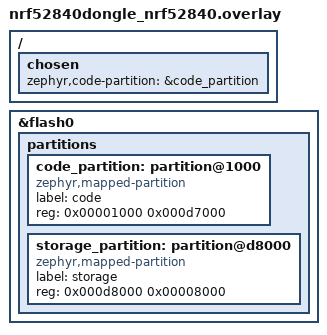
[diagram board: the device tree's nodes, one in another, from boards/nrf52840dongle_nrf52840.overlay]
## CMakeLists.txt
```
# Cremind Tag gateway firmware (docs/gateway-firmware.md). Built by
# tools/build.py with -DZEPHYR_EXTRA_MODULES=<repository>, which provides lib/.
cmake_minimum_required(VERSION 3.20.0)
find_package(Zephyr REQUIRED HINTS $ENV{ZEPHYR_BASE})
project(cremind_gateway)

target_sources(app PRIVATE
  src/main.c
  src/mesh.c
  src/store.c
  src/gw_thread.c
  src/uart_io.c
  src/core/gw_core.c
  src/core/gw_serial.c
  src/core/gw_lane.c
  src/core/gw_delivery.c
  src/core/gw_nodes.c
  src/core/gw_ring.c)
# Protocol v2 (docs/connect-setup.md): secure sessions, ownership, tunnels,
# and the physical factory reset.
target_sources_ifdef(CONFIG_CTAG_GW_SECURE app PRIVATE
  src/reset.c
  src/core/gw_secure.c
  src/core/gw_tunnel.c)
# Tags on the gateway's own radio (docs/protocol.md 11): the relay core and
# its Bluetooth side (lib/sched and lib/frag come with CONFIG_CTAG_GW_RADIO).
target_sources_ifdef(CONFIG_CTAG_GW_RADIO app PRIVATE
  src/central.c
  src/core/gw_radio.c)
target_include_directories(app PRIVATE src src/core)
```

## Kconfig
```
# Cremind Tag gateway application options (docs/gateway-firmware.md).

rsource "Kconfig.gateway"

source "Kconfig.zephyr"
```

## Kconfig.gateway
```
# Gateway options shared by the application (Kconfig) and its native_sim
# builds (tests/*/Kconfig). docs/gateway-firmware.md explains each.

menu "Cremind Tag gateway"

config CTAG_GW_BOARD_ID
	int "Protocol board id reported in caps.board"
	default 1
	help
	  protocol/spec.yaml boards: 1 = NRF52840DK_GATEWAY, 2 =
	  NRF52832_GATEWAY. Set per SoC in socs/<soc>.conf.

config CTAG_GW_SERIAL_CREDITS
	int "Serial: requests the host may have outstanding (caps.credits)"
	default 4
	range 1 32
	help
	  Every request is processed as soon as its frame completes; its
	  response waits in one of these slots until the host grants a credit.
	  The credit of a request is returned with its response.

config CTAG_GW_TX_FRAME
	int "Serial: largest decoded frame the gateway sends (bytes)"
	default 2048
	range 512 4096
	help
	  Bounds INFO, LIST_NODES and GET_INVENTORY answers and EVT_BRIDGE_INFO.
	  A full inventory (MAX_BRIDGES bridges, MAX_TAGS assignments, health
	  counters) needs about 1.9 KiB.

config CTAG_GW_EVENT_MAX
	int "Serial: largest retained event payload (bytes)"
	default 104
	range 100 255
	help
	  One slot of the SERIAL_EVENT_RETAIN ring. EVT_RESULT, the largest
	  retained event, encodes to at most 100 bytes (every field at its
	  largest value, flags and stored_epoch included).

config CTAG_GW_EVQ_BYTES
	int "Serial: best-effort event FIFO (bytes)"
	default 1024
	range 256 8192
	help
	  EVT_STAGE, EVT_UNPROV_BEACON, EVT_TAG_SEEN, EVT_BRIDGE_INFO and EVT_LOG
	  waiting for a host credit; a full FIFO drops the new event
	  (events_discarded).

config CTAG_GW_DELIVERY_QUEUE
	int "Delivery queue: layouts waiting behind the active transfer"
	default 4
	range 1 16
	help
	  DELIVER_LAYOUT answers BUSY when this many layouts are queued, or when
	  the layout arena has no room for the new one.

config CTAG_GW_LAYOUT_ARENA
	int "Delivery queue: bytes for the queued and active layouts"
	default 20480
	range 4096 65536
	help
	  Layouts are stored back to back (4-byte header, 4-byte aligned) and
	  released in order. At least CTAG_GW_LAYOUT_MAX + 4 so that the largest
	  layout always fits an empty queue; typical layouts are about 1 KiB.

config CTAG_GW_LAYOUT_MAX
	int "Delivery queue: largest layout accepted (bytes)"
	default 4000
	range 150 4096
	help
	  LAYOUT_SERIAL_MAX (4000) is the largest layout the companion sends;
	  anything larger answers TOO_LARGE.

config CTAG_GW_AT_BRIDGE
	int "Deliveries remembered while their bridge works on them"
	default 16
	range 1 64
	help
	  Validated layouts waiting for their DELIVERY_RESULT (for CANCEL_DELIVERY
	  and timing.mesh_ms). The oldest entry is forgotten when full.

config CTAG_GW_MESH_OPS
	int "ASSIGN_TAG / UNASSIGN_TAG / TAG_COMMAND operations in flight"
	default 8
	range 1 32

config CTAG_GW_RESULT_DEDUP
	int "(bridge, result_seq) pairs remembered for de-duplication"
	default 64
	range 8 512

config CTAG_GW_REPORTED
	int "update_ids remembered as reported (one EVT_RESULT each)"
	default 64
	range 8 512
	help
	  docs/protocol.md 10: exactly one EVT_RESULT per update_id. A later
	  result for a remembered update_id is acknowledged to the bridge and
	  dropped.

config CTAG_GW_ASSIGN_MAX
	int "Assignments remembered for the inventory"
	default 32
	range 1 128

config CTAG_GW_NAME_MAX
	int "Longest bridge name kept (bytes)"
	default 32
	range 8 64

config CTAG_GW_UNSEG_QUEUE
	int "Unsegmented mesh messages waiting for an advertising buffer"
	default 16
	range 4 64

config CTAG_GW_TAG_SEEN_INTERVAL_MS
	int "EVT_TAG_SEEN: minimum interval per (bridge, tag) (ms)"
	default 10000
	range 0 600000

config CTAG_GW_STATUS_TIMEOUT_MS
	int "LAYOUT_STATUS wait after a commit (ms)"
	default 10000

config CTAG_GW_REPLY_TIMEOUT_MS
	int "ASSIGN_STATUS and configuration-client reply wait (ms)"
	default 5000

config CTAG_GW_PROVISION_TIMEOUT_MS
	int "Provisioning guard: EVT_PROVISIONED TIMEOUT after (ms)"
	default 90000

config CTAG_GW_UART_RX_RING
	int "Serial driver: receive ring (bytes)"
	default 1024

config CTAG_GW_UART_TX_RING
	int "Serial driver: transmit ring (bytes)"
	default 1024

config CTAG_GW_EVQ_DEPTH
	int "Mesh/provisioning events queued for the gateway loop"
	default 24

config CTAG_GW_SECURE
	bool "Protocol v2: identity, ownership and secure sessions"
	select CTAG_SECURE
	help
	  docs/connect-setup.md: IDENTIFY, SECURE_OPEN and SECURE_DATA in
	  plaintext, everything else only inside a Noise IK session and only
	  as the access table of 4.2 allows; CLAIM, RECOVER, RELEASE, STATUS;
	  PROVISION with static OOB; DISCOVER and mesh tunnels. Without it the
	  gateway speaks protocol v1 (docs/gateway-firmware.md says which
	  boards run which).

if CTAG_GW_SECURE

config CTAG_GW_TUNNELS
	int "Mesh tunnels open at once (one per bridge)"
	default 2
	range 1 5

config CTAG_GW_DISCOVERED_SLOTS
	int "EVT_DISCOVERED rate limiter entries ((bridge, tag) pairs)"
	default 16
	range 4 64

config CTAG_GW_RADIO
	bool "Tags on the gateway's own radio (docs/protocol.md 11)"
	select CTAG_SCHED
	select CTAG_FRAG
	help
	  The gateway also connects to tags itself, as a thin BLE relay:
	  TUNNEL_OPEN / DISCOVER with bridge GATEWAY_ADDR use its own radio,
	  the companion runs the tag session and renders, and the gateway
	  carries whole messages (fragmented per 5.3) between the serial
	  tunnel and the tag's characteristics. Connections follow the mesh
	  suspend window of 5.2 (lib/sched). Protocol v2 only (it depends on
	  CTAG_GW_SECURE: tunnels and DISCOVER are v2 messages). Needs
	  BT_CENTRAL and BT_GATT_CLIENT; HELLO caps report tag_links.

if CTAG_GW_RADIO

config CTAG_GW_TAG_LINKS
	int "Tag connections held at once (caps.tag_links)"
	default 2
	range 1 2
	help
	  One Bluetooth connection each (CONFIG_BT_MAX_CONN >= this) and, per
	  link, the transmit queue of its tunnel (two messages) and the
	  reassembly buffers of what the tag sends.

config CTAG_GW_RADIO_TUNNELS
	int "Own-radio tunnels open at once (waiting or connected)"
	default 8
	range 1 16
	help
	  TUNNEL_OPEN to GATEWAY_ADDR answers BUSY beyond this. A waiting
	  tunnel costs a few bytes; its buffers are the link's once it is
	  connected.

config CTAG_GW_LINK_INFLIGHT
	int "DATA fragments handed to the Bluetooth host at once, per link"
	default 4
	range 1 16
	help
	  Writes without response in flight on one link. Kept below
	  CONFIG_BT_ATT_TX_COUNT (times the links) so that a write never
	  waits for an ATT buffer on the gateway loop.

# The shared scheduler (lib/sched): one link per tag link (gw_radio.c asserts
# it) and a back-off entry per tag it may be trying (one per own-radio tunnel
# at the default).
config CTAG_SCHED_LINKS
	default CTAG_GW_TAG_LINKS

config CTAG_SCHED_TAGS
	default 8

endif # CTAG_GW_RADIO

endif

endmenu
```

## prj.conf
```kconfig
# Cremind Tag gateway: every target. Per-SoC fragments in socs/, per-board in
# boards/ (docs/building.md). Debug logging over RTT: debug/rtt.conf
# (docs/gateway-firmware.md "Debugging").

# ---- Libraries (docs/firmware-libs.md) ----
CONFIG_CTAG_FRAME=y
CONFIG_CTAG_CBOR=y

# ---- Bluetooth: the Zephyr controller (bt-ll-sw-split snippet); the mesh
# needs only an observer and a broadcaster, never a connection. The nRF52840's
# tag links on its own radio add a central with a GATT client
# (socs/nrf52840.conf) ----
CONFIG_BT=y
CONFIG_BT_OBSERVER=y
CONFIG_BT_BROADCASTER=y
CONFIG_BT_CENTRAL=n
CONFIG_BT_PERIPHERAL=n
CONFIG_BT_SMP=n
CONFIG_BT_SETTINGS=y
CONFIG_BT_DEVICE_NAME="Cremind Tag gateway"
# Keep controller crypto (firmware-notes correction 8).
CONFIG_BT_CTLR_CRYPTO=y
CONFIG_BT_CTLR_DUP_FILTER_LEN=0
CONFIG_BT_CTLR_PRIVACY=n

# ---- Bluetooth Mesh: provisioner, CDB, configuration client (protocol.md 2) ----
CONFIG_BT_MESH=y
CONFIG_BT_MESH_PROVISIONER=y
CONFIG_BT_MESH_PROVISIONEE=n
CONFIG_BT_MESH_PB_ADV=y
CONFIG_BT_MESH_PB_GATT=n
CONFIG_BT_MESH_GATT_PROXY=n
CONFIG_BT_MESH_FRIEND=n
CONFIG_BT_MESH_LOW_POWER=n
CONFIG_BT_MESH_RELAY=n
CONFIG_BT_MESH_CDB=y
# The gateway itself plus MAX_BRIDGES bridges.
CONFIG_BT_MESH_CDB_NODE_COUNT=6
CONFIG_BT_MESH_CDB_SUBNET_COUNT=1
CONFIG_BT_MESH_CDB_APP_KEY_COUNT=1
CONFIG_BT_MESH_SUBNET_COUNT=1
CONFIG_BT_MESH_APP_KEY_COUNT=1
CONFIG_BT_MESH_MODEL_KEY_COUNT=1
CONFIG_BT_MESH_MODEL_GROUP_COUNT=1
CONFIG_BT_MESH_LABEL_COUNT=0
CONFIG_BT_MESH_CFG_CLI=y
CONFIG_BT_MESH_HEALTH_CLI=y
# Never the legacy advertiser (firmware-notes correction 4).
CONFIG_BT_MESH_ADV_EXT=y
CONFIG_BT_MESH_DEFAULT_TTL=5
CONFIG_BT_MESH_NETWORK_TRANSMIT_COUNT=3
CONFIG_BT_MESH_NETWORK_TRANSMIT_INTERVAL=20
# 160-byte vendor parameters need >= MESH_MIN_SEG segments. The gateway sends
# one segmented message at a time (3.2 rule 1); the second slot only absorbs a
# configuration-client message whose status came before its segment ACK.
CONFIG_BT_MESH_TX_SEG_MAX=16
CONFIG_BT_MESH_RX_SEG_MAX=16
CONFIG_BT_MESH_TX_SEG_MSG_COUNT=2
# Results (DELIVERY_RESULT, 44 access bytes) from several bridges at once.
CONFIG_BT_MESH_RX_SEG_MSG_COUNT=4
CONFIG_BT_MESH_ADV_BUF_COUNT=16
CONFIG_BT_MESH_CRPL=16
# Replay list written every 10 minutes, not on every message (flash wear).
CONFIG_BT_MESH_RPL_STORE_TIMEOUT=600

# ---- Storage: mesh state and the gateway's records (settings on NVS) ----
# Link into the code partition so the image can never grow into the settings.
CONFIG_USE_DT_CODE_PARTITION=y
CONFIG_FLASH=y
CONFIG_FLASH_MAP=y
CONFIG_FLASH_PAGE_LAYOUT=y
CONFIG_NVS=y
CONFIG_SETTINGS=y

# ---- Crypto: PSA (the mesh requires it); SHA-256 for the layout digest ----
CONFIG_PSA_WANT_ALG_SHA_256=y
CONFIG_ENTROPY_GENERATOR=y
# With BT_SETTINGS every mesh key is a persistent PSA key (secure storage):
# the subnet's derived keys, the app key, the device key, and in the CDB the
# net key, the app key and one device key per node (MAX_BRIDGES + 1), plus the
# provisioning ECDH key (firmware-notes 3). NCS defaults to 16 slots.
CONFIG_MBEDTLS_PSA_KEY_SLOT_COUNT=24

# ---- Advertising: the provisioner's own messages only (no relay, proxy or
# friend sets; NCS sizes 5 for a relay node) ----
CONFIG_BT_EXT_ADV_MAX_ADV_SET=1
CONFIG_BT_CTLR_ADV_SET=1

# ---- Kernel and drivers ----
CONFIG_SERIAL=y
CONFIG_UART_INTERRUPT_DRIVEN=y
CONFIG_RING_BUFFER=y
CONFIG_HWINFO=y
CONFIG_REBOOT=y
# Bluetooth API from cooperative threads only (the mesh provisioner sample).
CONFIG_MAIN_THREAD_PRIORITY=-2

# ---- Release build: no console or logging (the serial link belongs to the
# companion); debug/rtt.conf routes logs to RTT. ----
CONFIG_LOG=n
CONFIG_CONSOLE=n
CONFIG_UART_CONSOLE=n
CONFIG_PRINTK=n
CONFIG_ASSERT=n
CONFIG_BOOT_BANNER=n
CONFIG_NCS_BOOT_BANNER=n
```

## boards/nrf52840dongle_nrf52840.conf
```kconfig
# nRF52840 Dongle gateway (boards/nrf52840dongle_nrf52840.overlay). The board
# makes its USB port a CDC ACM console by default; here the port belongs to
# the companion's link alone (socs/nrf52840.conf), as on the DK.
CONFIG_BOARD_SERIAL_BACKEND_CDC_ACM=n
```

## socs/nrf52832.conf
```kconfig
# nRF52832 gateway (board id NRF52832_GATEWAY): UART (CH340 on the board, the
# interface MCU's virtual COM port on the nRF52 DK), 64 KiB RAM. Subject to
# resource qualification (docs/qualification/nrf52832_gateway.md).
CONFIG_CTAG_GW_BOARD_ID=2

# Stacks trimmed from the provisioner sample's figures; must be re-measured
# with debug/rtt.conf (CONFIG_THREAD_ANALYZER) during qualification. main runs
# the start-up and then the gateway loop.
CONFIG_MAIN_STACK_SIZE=3072
CONFIG_SYSTEM_WORKQUEUE_STACK_SIZE=2560
CONFIG_BT_MESH_SETTINGS_WORKQ_STACK_SIZE=1400
CONFIG_BT_MESH_ADV_STACK_SIZE=2048
CONFIG_BT_RX_STACK_SIZE=2560

# Delivery queue: up to three layouts behind the active one, within a 5 KiB
# arena (one LAYOUT_SERIAL_MAX layout plus a typical ~1 KiB one, or four
# typical ones); BUSY beyond.
CONFIG_CTAG_GW_DELIVERY_QUEUE=3
CONFIG_CTAG_GW_LAYOUT_ARENA=5120
CONFIG_CTAG_GW_TX_FRAME=2048
CONFIG_CTAG_GW_EVQ_BYTES=768
CONFIG_CTAG_GW_UART_RX_RING=768
CONFIG_CTAG_GW_UART_TX_RING=256
CONFIG_CTAG_GW_AT_BRIDGE=12
CONFIG_CTAG_GW_RESULT_DEDUP=32
CONFIG_CTAG_GW_REPORTED=32
CONFIG_CTAG_GW_ASSIGN_MAX=24
CONFIG_CTAG_GW_EVQ_DEPTH=16

# Host and mesh buffers: no connections, so few HCI event buffers; adverts
# arrive in the discardable pool.
CONFIG_BT_BUF_EVT_RX_COUNT=4
CONFIG_BT_BUF_EVT_DISCARDABLE_COUNT=10
CONFIG_BT_MESH_ADV_BUF_COUNT=10
CONFIG_BT_MESH_RX_SEG_MSG_COUNT=2
CONFIG_BT_MESH_MSG_CACHE_SIZE=16
CONFIG_BT_MESH_CRPL=8
CONFIG_MBEDTLS_PSA_KEY_SLOT_COUNT=20
```

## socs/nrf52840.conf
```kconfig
# nRF52840 gateway (board id NRF52840DK_GATEWAY): USB CDC ACM, 256 KiB RAM.
CONFIG_CTAG_GW_BOARD_ID=1

# Host link: USB CDC ACM with the device_next stack (firmware-notes 7). The
# USB serial number is the device id (HWINFO): the companion's gateway id.
CONFIG_USB_DEVICE_STACK_NEXT=y
CONFIG_CDC_ACM_SERIAL_INITIALIZE_AT_BOOT=y
CONFIG_UART_LINE_CTRL=y
CONFIG_CDC_ACM_SERIAL_MANUFACTURER_STRING="Cremind"
CONFIG_CDC_ACM_SERIAL_PRODUCT_STRING="Cremind Tag gateway"
# pid.codes test VID/PID (1209:0002), not the Zephyr sample default: replace
# with an allocated pair before shipping hardware.
CONFIG_CDC_ACM_SERIAL_VID=0x1209
CONFIG_CDC_ACM_SERIAL_PID=0x0002

# Entropy from the RNG peripheral, never the CryptoCell library
# (firmware-notes correction 9; socs/nrf52840.overlay chooses &rng).
CONFIG_ENTROPY_CC3XX=n

# Stacks from the Zephyr mesh provisioner sample's thread analysis (+50 %);
# re-measure with debug/rtt.conf (CONFIG_THREAD_ANALYZER) on hardware. main
# runs the start-up (settings, self-configuration) and then the gateway loop,
# which under v2 also runs X25519, Ed25519 and ChaCha20-Poly1305: the static
# call-graph analysis (-fstack-usage -fcallgraph-info, docs/gateway-firmware.md
# 15.11) puts its deepest chain at 9,916 B, through HACL*'s Ed25519
# verification (a 6,432-byte frame: two precomputed point tables) under a
# grant check. 12 KiB leaves ~2.3 KiB for exception frames and the chains the
# analysis cannot follow (function pointers: settings writes, the RNG).
CONFIG_MAIN_STACK_SIZE=12288
CONFIG_SYSTEM_WORKQUEUE_STACK_SIZE=4096
CONFIG_BT_MESH_SETTINGS_WORKQ_STACK_SIZE=1700
CONFIG_BT_MESH_ADV_STACK_SIZE=4000
CONFIG_BT_RX_STACK_SIZE=3300

# Protocol v2 (docs/connect-setup.md, docs/gateway-firmware.md "Protocol v2"):
# device identity, ownership, Noise IK sessions (lib/secure: Noise* + HACL*),
# static-OOB provisioning, DISCOVER and tunnels, the button factory reset.
# The secure heap holds a session (~0.8 KiB) and twice the largest sealed or
# opened message (a 4 KiB SECURE_DATA carrying a full DELIVER_LAYOUT).
CONFIG_CTAG_GW_SECURE=y
CONFIG_CTAG_SECURE_HEAP_SIZE=12288
CONFIG_CTAG_GW_TUNNELS=2
# connect-setup.md 3.4: static OOB over HMAC-SHA256 only (the provisioner's
# capabilities callback refuses anything else; the option below only affects
# the gateway's own provisionee role, which it never uses over PB-ADV).
CONFIG_BT_MESH_ECDH_P256_HMAC_SHA256_AES_CCM=y
CONFIG_BT_MESH_OOB_AUTH_REQUIRED=y
# The factory-reset button and LED (reset.c).
CONFIG_GPIO=y

# Tags on the gateway's own radio (docs/protocol.md 11, docs/gateway-firmware.md
# 16): two tag links (caps.tag_links), eight own-radio tunnels, the shared
# connection scheduler (lib/sched) and GATT fragmentation (lib/frag). The
# Bluetooth options are the bridge's for a central with a GATT client
# (apps/bridge/prj.conf): ATT MTU 23 (fragments of ATT_VALUE_MAX bytes), no
# automatic parameter updates or GATT caching, and TX buffers above the DATA
# fragments of both links in flight (2 x CTAG_GW_LINK_INFLIGHT = 8 < 12, a
# write never waits on the gateway loop; central.c asserts it); the host
# wants more HCI event buffers than ACL TX buffers.
CONFIG_CTAG_GW_RADIO=y
CONFIG_CTAG_GW_TAG_LINKS=2
CONFIG_CTAG_GW_RADIO_TUNNELS=8
CONFIG_CTAG_GW_LINK_INFLIGHT=4
CONFIG_BT_CENTRAL=y
CONFIG_BT_GATT_CLIENT=y
CONFIG_BT_MAX_CONN=2
CONFIG_BT_GATT_CACHING=n
CONFIG_BT_GAP_AUTO_UPDATE_CONN_PARAMS=n
CONFIG_BT_L2CAP_TX_MTU=23
CONFIG_BT_BUF_ACL_RX_SIZE=27
CONFIG_BT_BUF_ACL_TX_SIZE=27
CONFIG_BT_ATT_TX_COUNT=12
CONFIG_BT_L2CAP_TX_BUF_COUNT=12
CONFIG_BT_BUF_ACL_TX_COUNT=12
CONFIG_BT_BUF_EVT_RX_COUNT=16

# Room for the full protocol: four queued layouts behind the active one, all
# of them LAYOUT_SERIAL_MAX bytes if need be.
CONFIG_CTAG_GW_DELIVERY_QUEUE=4
CONFIG_CTAG_GW_LAYOUT_ARENA=20480
CONFIG_CTAG_GW_TX_FRAME=2560
CONFIG_CTAG_GW_EVQ_BYTES=2048
CONFIG_CTAG_GW_UART_RX_RING=1024
CONFIG_CTAG_GW_UART_TX_RING=1024
```

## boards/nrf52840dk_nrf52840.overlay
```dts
/*
 * nRF52840 DK gateway. No bootloader: the image links from 0 into
 * code_partition, which ends where the settings storage (mesh state, CDB,
 * names, assignments: the DK's 32 KiB storage_partition) begins, so the
 * linker refuses an image that would grow into it.
 */
/ {
	chosen {
		zephyr,code-partition = &code_partition;
	};
};

/delete-node/ &boot_partition;
/delete-node/ &slot0_partition;
/delete-node/ &slot1_partition;

&flash0 {
	partitions {
		code_partition: partition@0 {
			compatible = "zephyr,mapped-partition";
			label = "code";
			reg = <0x00000000 0x000f8000>;
		};
	};
};
```

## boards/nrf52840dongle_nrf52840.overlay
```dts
/*
 * nRF52840 Dongle (PCA10059) gateway, loaded by Nordic's factory USB
 * bootloader (docs/building.md "nRF52840 Dongle"). The MBR owns 0x0-0x1000
 * and the bootloader 0xe0000 to the end of flash, so the image links from
 * 0x1000 into code_partition, which ends where the settings storage (mesh
 * state, CDB, names, assignments: 32 KiB, as on the DK) begins, and the
 * linker refuses an image that would grow into it.
 *
 * The board's own CDC ACM console (boards/common/usb/cdc_acm_serial.dtsi)
 * goes: the USB port carries one CDC ACM function, the companion's link
 * (socs/nrf52840.overlay), as on the DK's nRF USB port.
 */
/ {
	chosen {
		zephyr,code-partition = &code_partition;
		/delete-property/ zephyr,console;
		/delete-property/ zephyr,shell-uart;
		/delete-property/ zephyr,uart-mcumgr;
		/delete-property/ zephyr,bt-mon-uart;
		/delete-property/ zephyr,bt-c2h-uart;
	};
};

/delete-node/ &board_cdc_acm_uart;
/delete-node/ &boot_partition;
/delete-node/ &slot0_partition;
/delete-node/ &slot1_partition;
/delete-node/ &storage_partition;

&flash0 {
	partitions {
		code_partition: partition@1000 {
			compatible = "zephyr,mapped-partition";
			label = "code";
			reg = <0x00001000 0x000d7000>;
		};

		/* Ends at the bootloader (0xe0000). */
		storage_partition: partition@d8000 {
			compatible = "zephyr,mapped-partition";
			label = "storage";
			reg = <0x000d8000 0x00008000>;
		};
	};
};
```

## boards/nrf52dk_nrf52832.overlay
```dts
/*
 * nRF52 DK gateway (development stand-in for the nRF52832 + CH340 board).
 * No bootloader: the image links from 0 into code_partition, which ends where
 * the DK's 24 KiB storage_partition (settings) begins.
 */
/ {
	chosen {
		zephyr,code-partition = &code_partition;
	};
};

/delete-node/ &boot_partition;
/delete-node/ &slot0_partition;
/delete-node/ &slot1_partition;

&flash0 {
	partitions {
		code_partition: partition@0 {
			compatible = "zephyr,mapped-partition";
			label = "code";
			reg = <0x00000000 0x0007a000>;
		};
	};
};
```

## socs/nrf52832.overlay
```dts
/* nRF52832 gateway: the companion's link on the UART (115200 8N1). */
/ {
	chosen {
		cremind,gateway-uart = &uart0;
	};
};
```

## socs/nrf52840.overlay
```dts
/*
 * nRF52840 gateway: entropy from the RNG peripheral (firmware-notes
 * correction 9) and the companion's link on a USB CDC ACM UART.
 */
/ {
	chosen {
		zephyr,entropy = &rng;
		cremind,gateway-uart = &cdc_acm_uart0;
	};
};

&zephyr_udc0 {
	cdc_acm_uart0: cdc_acm_uart0 {
		compatible = "zephyr,cdc-acm-uart";
	};
};
```

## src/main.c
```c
/*
 * Cremind Tag gateway (docs/gateway-firmware.md): the companion's serial link
 * (USB CDC ACM on the nRF52840, the UART on the nRF52832) to a Bluetooth Mesh
 * provisioner that delivers layouts to the bridges.
 *
 * main() starts the serial port (bytes are buffered while the mesh starts),
 * brings up Bluetooth, the mesh and the network from settings, draws a fresh
 * boot_id, loads the CDB into the core and then becomes the gateway loop
 * (gw_thread.c), which never returns.
 *
 * Protocol v2 (CONFIG_CTAG_GW_SECURE, docs/connect-setup.md): before the mesh
 * starts, a board button held through power-up for 10 s is the physical
 * factory reset; the identity key is generated with the hardware RNG at
 * first boot and kept in settings; the ownership record and the generation
 * floor are loaded; an unowned gateway never keeps a network (a released or
 * reset one, or a v1 network found at the first v2 boot, is wiped).
 *
 * Tags on the own radio (CONFIG_CTAG_GW_RADIO, docs/protocol.md 11): once the
 * mesh runs, central.c listens to its scan for tag advertisements and serves
 * the core's link operations.
 */
#include <zephyr/device.h>
#include <zephyr/kernel.h>
#include <zephyr/logging/log.h>
#include <zephyr/random/random.h>
#include <zephyr/sys/reboot.h>
#include <zephyr/sys/util.h>

#include <app_version.h>
#include <psa/crypto.h>

#include "gw_app.h"
#include "gw_mesh.h"

LOG_MODULE_REGISTER(gateway, LOG_LEVEL_INF);

#define GW_UART DEVICE_DT_GET(DT_CHOSEN(cremind_gateway_uart))

#if defined(APP_BUILD_VERSION)
#define GW_BUILD STRINGIFY(APP_BUILD_VERSION)
#else
#define GW_BUILD "unknown"
#endif

static struct gw_core core;

static size_t be_write(void *ctx, const uint8_t *data, size_t len)
{
	ARG_UNUSED(ctx);
	return uart_io_write(data, len);
}

static void be_reboot(void *ctx)
{
	ARG_UNUSED(ctx);
	/* 10: the REBOOT answer is out of the ring; give the UART / USB FIFO a
	 * moment, then reset (USB re-enumerates, a new boot_id follows). */
	uart_io_flush(K_MSEC(200));
	k_sleep(K_MSEC(50));
	sys_reboot(SYS_REBOOT_COLD);
}

static size_t be_counters(void *ctx, struct ctag_cbor_counter *items, size_t max)
{
	size_t n = uart_io_counters(items, max);

	ARG_UNUSED(ctx);
	n += gw_mesh_counters(&items[n], max - n);
#ifdef CONFIG_CTAG_GW_RADIO
	n += gw_central_counters(&items[n], max - n);
#endif
	return n;
}

#ifdef CONFIG_CTAG_GW_SECURE
static int be_random(void *ctx, uint8_t *buf, size_t len)
{
	ARG_UNUSED(ctx);
	return sys_csrand_get(buf, len);
}
#endif

static const struct gw_backend backend = {
	.write = be_write,
	.reboot = be_reboot,
	.mesh_send = gw_mesh_send,
	.mesh_cfg = gw_mesh_cfg,
	.provision = gw_mesh_provision,
	.node_configured = gw_mesh_node_configured,
	.node_delete = gw_mesh_node_delete,
	.store_name = gw_store_name,
	.store_assignments = gw_store_assignments,
	.sha256 = gw_sha256,
	.counters = be_counters,
#ifdef CONFIG_CTAG_GW_SECURE
	.store_owner = gw_store_save_owner,
	.random = be_random,
	.release = gw_mesh_wipe,
#endif
#ifdef CONFIG_CTAG_GW_RADIO
	.radio_listen = gw_central_listen,
	.radio_suspend = gw_central_suspend,
	.radio_resume = gw_central_resume,
	.link_connect = gw_central_connect,
	.link_disconnect = gw_central_disconnect,
	.link_setup = gw_central_setup,
	.link_write = gw_central_write,
#endif
};

#ifdef CONFIG_CTAG_GW_SECURE
/* The identity key: from settings, or generated now (first boot). */
static void load_identity(uint8_t ik[32])
{
	if (gw_store_identity(ik)) {
		return;
	}
	while (sys_csrand_get(ik, 32u) != 0) {
		/* The entropy driver not ready yet: an identity is never weakened. */
		k_sleep(K_MSEC(10));
	}
	if (gw_store_save_identity(ik) != 0) {
		LOG_ERR("identity key not stored");
	}
	LOG_INF("new identity key");
}

/*
 * The v2 part of start-up; true = the gateway must reboot (a factory reset
 * or a stale network was wiped, and the next boot creates a new network).
 */
static bool secure_boot(bool factory_reset)
{
	uint8_t ik[32];
	const uint8_t *rec;
	size_t rec_len;
	uint32_t floor;
	struct ctag_secure_ep *ep = &core.v2.ep;

	load_identity(ik);
	gw_store_owner(&rec, &rec_len, &floor);
	gw_core_secure_init(&core, ik, rec, rec_len, floor);
	ctag_secure_wipe(ik, sizeof(ik));
	if (factory_reset) {
		/* 4.3: ownership, mesh and assignments go; identity and generation stay. */
		struct ctag_owner_record r = {.state = CTAG_OWNER_UNOWNED, .gen = ep->rec.gen};
		uint8_t raw[CTAG_OWNER_RECORD_LEN];

		ctag_owner_record_encode(&r, raw);
		(void)gw_store_save_owner(NULL, raw, r.gen);
		gw_mesh_wipe(NULL);
		LOG_WRN("factory reset (generation %u kept)", r.gen);
		return true;
	}
	if (ep->rec.state != CTAG_OWNER_OWNED &&
	    (gw_node_count(&core) > 0u || core.assign_count > 0u)) {
		/* A network belongs to an owner: an unowned gateway never serves one. */
		gw_mesh_wipe(NULL);
		LOG_WRN("unowned gateway: stale network wiped");
		return true;
	}
	return false;
}
#endif

int main(void)
{
	struct gw_info info = {
		.fw = APP_VERSION_STRING,
		.build = GW_BUILD,
		.board = CONFIG_CTAG_GW_BOARD_ID,
	};
	int err;
#ifdef CONFIG_CTAG_GW_SECURE
	/* Before anything else: the button held through power-up (10 s). */
	bool factory_reset = gw_factory_reset_held();
#endif

	err = uart_io_init(GW_UART);
	if (err != 0) {
		LOG_ERR("serial port not ready: %d", err);
	}
	/* The mesh initialises PSA too; the layout digest needs it even if the
	 * mesh does not come up. */
	(void)psa_crypto_init();
	err = gw_mesh_start();
	if (err != 0) {
		/* Keep serving the host: INFO shows mesh_init, requests to bridges fail. */
		LOG_ERR("mesh unavailable: %d", err);
	}
#ifdef CONFIG_CTAG_GW_RADIO
	if (err == 0) {
		/* Tags on the own radio are heard through the mesh's scan: once it runs. */
		gw_central_init();
	}
#endif
	if (sys_csrand_get(&info.boot_id, sizeof(info.boot_id)) != 0) {
		info.boot_id = sys_rand32_get();
	}
	gw_core_init(&core, &backend, &info, k_uptime_get());
	gw_mesh_load_nodes(&core);
	gw_store_apply(&core);
#ifdef CONFIG_CTAG_GW_SECURE
	if (secure_boot(factory_reset)) {
		k_sleep(K_MSEC(1000)); /* the LED stays solid for a moment */
		sys_reboot(SYS_REBOOT_COLD);
	}
#endif
	LOG_INF("gateway %s (%s) boot_id %08x, %u bridges", info.fw, info.build, info.boot_id,
		gw_node_count(&core));
	gw_run(&core); /* the gateway loop keeps main (and its stack) */
}
```

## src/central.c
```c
/*
 * The gateway's own radio, Bluetooth side (docs/protocol.md 11,
 * docs/gateway-firmware.md 16; CONFIG_CTAG_GW_RADIO): tag advertisements
 * from the mesh's own scan (bt_le_scan_cb_register: the gateway never starts
 * or stops scanning), the connections of the 5.2 window, per link the GATT
 * setup of the tunnel's mode (discovery of the tag service, the CCC
 * subscriptions, the read of CAPS or IDENT), and the fragments the core
 * writes. The core (src/core/gw_radio.c, lib/sched) decides everything; this
 * file only runs the Bluetooth procedures it asks for (struct gw_backend).
 *
 * Callbacks run in Bluetooth contexts and only post events (gw_post); the
 * discovery and read callbacks also collect handles and value bytes into
 * their link's record, which the gateway thread reads only after that
 * procedure's completion event (the event queue orders them). Everything
 * else here is owned by the gateway thread.
 */
#include <errno.h>
#include <string.h>

#include <zephyr/bluetooth/bluetooth.h>
#include <zephyr/bluetooth/conn.h>
#include <zephyr/bluetooth/gatt.h>
#include <zephyr/bluetooth/hci.h>
#include <zephyr/bluetooth/mesh.h>
#include <zephyr/bluetooth/uuid.h>
#include <zephyr/kernel.h>
#include <zephyr/logging/log.h>
#include <zephyr/sys/atomic.h>
#include <zephyr/sys/byteorder.h>
#include <zephyr/sys/util.h>

#include "gw_app.h"
#include "gw_mesh.h"

LOG_MODULE_REGISTER(gw_central, LOG_LEVEL_INF);

#define LINKS        CONFIG_CTAG_GW_TAG_LINKS
#define ADV_MSD_LEN  10u /* company u16, ver u8, tag_id u32, flags u8, disp_rev u16 (5.1) */
#define CONN_INT_MIN 24  /* 30 ms (1.25 ms units) */
#define CONN_INT_MAX 40  /* 50 ms */
#define CONN_TIMEOUT 400 /* 4 s (10 ms units) */
#define READ_MAX     GW_EVT_DATA /* the value read goes up in one event */

/* One connection per link; the DATA fragments of every link in flight at once
 * stay below the ATT, L2CAP and ACL buffers, so a write from the gateway loop
 * never waits for one (the host allocates them with K_FOREVER there). */
BUILD_ASSERT(CONFIG_BT_MAX_CONN >= LINKS, "a Bluetooth connection per tag link");
BUILD_ASSERT(LINKS * CONFIG_CTAG_GW_LINK_INFLIGHT < CONFIG_BT_ATT_TX_COUNT,
	     "DATA fragments in flight must stay below the ATT buffers");
BUILD_ASSERT(LINKS * CONFIG_CTAG_GW_LINK_INFLIGHT < CONFIG_BT_L2CAP_TX_BUF_COUNT,
	     "DATA fragments in flight must stay below the L2CAP buffers");
BUILD_ASSERT(LINKS * CONFIG_CTAG_GW_LINK_INFLIGHT < CONFIG_BT_BUF_ACL_TX_COUNT,
	     "DATA fragments in flight must stay below the ACL buffers");
BUILD_ASSERT(CTAG_TAG_CAPS_LEN <= READ_MAX && CTAG_IDENT2_LEN <= READ_MAX,
	     "the CAPS or IDENT value fits one event");
BUILD_ASSERT(CTAG_ATT_VALUE_MAX <= GW_EVT_DATA, "a notified value fits one event");
BUILD_ASSERT(sizeof(struct bt_conn *) <= GW_EVT_DATA, "a connection pointer fits one event");

static const struct bt_uuid_128 svc_uuid = BT_UUID_INIT_128(CTAG_GATT_SERVICE_UUID_VAL);
static const struct bt_uuid_128 caps_uuid = BT_UUID_INIT_128(CTAG_GATT_CHR_CAPS_UUID_VAL);
static const struct bt_uuid_128 ctrl_uuid = BT_UUID_INIT_128(CTAG_GATT_CHR_CTRL_UUID_VAL);
static const struct bt_uuid_128 data_uuid = BT_UUID_INIT_128(CTAG_GATT_CHR_DATA_UUID_VAL);
static const struct bt_uuid_128 status_uuid = BT_UUID_INIT_128(CTAG_GATT_CHR_STATUS_UUID_VAL);
static const struct bt_uuid_128 ident_uuid = BT_UUID_INIT_128(CTAG_GATT_CHR_IDENT_UUID_VAL);
static const struct bt_uuid_128 pair_uuid = BT_UUID_INIT_128(CTAG_GATT_CHR_PAIR_UUID_VAL);
/* Static, as every UUID a discovery is given: the stack keeps the pointer until
 * the procedure completes, and BT_UUID_GATT_CCC is a compound literal on the
 * caller's stack (gone once gatt_step returns: no CCC would ever match). */
static const struct bt_uuid_16 ccc_uuid = BT_UUID_INIT_16(BT_UUID_GATT_CCC_VAL);

enum phase {
	PH_IDLE = 0,
	PH_PRIMARY,   /* the tag service */
	PH_CHRC,      /* its characteristics */
	PH_CCC,       /* their CCC descriptors */
	PH_SUBSCRIBE, /* CTRL + STATUS, or PAIR */
	PH_READ,      /* CAPS or IDENT */
	PH_READY,
};

enum step { /* GW_EVT_GATT u16 */
	STEP_DISCOVERED = 1,
	STEP_SUBSCRIBED,
	STEP_READ,
};

struct handles {
	uint16_t start, end;
	uint16_t caps, ctrl, ctrl_ccc, data, status, status_ccc; /* SESSION */
	uint16_t ident, pair, pair_ccc;                          /* PAIR */
};

/* One tag connection. */
struct clink {
	struct bt_conn *conn;
	struct handles h; /* written by disc_cb during a discovery phase */
	uint8_t mode;     /* enum ctag_tunnel_mode */
	uint8_t phase;
	uint8_t subs;       /* subscriptions asked for */
	uint8_t subscribed; /* ... and confirmed */
	uint8_t sub_chr[2]; /* enum gw_chr of each subscription */
	uint8_t wr_chr;     /* the write with response in flight */
	uint16_t read_len;  /* written by read_cb during the read */
	struct bt_gatt_discover_params disc;
	struct bt_gatt_subscribe_params sub[2];
	struct bt_gatt_read_params rd;
	struct bt_gatt_write_params wr;
	uint8_t wr_buf[CTAG_ATT_VALUE_MAX];
	uint8_t read_buf[READ_MAX];
};

static struct clink links[LINKS];
static atomic_t listening;
static atomic_t adv_dropped;
static uint32_t gatt_failures;

static uint8_t index_of(const struct clink *cl)
{
	return (uint8_t)(cl - links);
}

/* The link whose record holds p (a callback's params). */
static struct clink *owner_of(const void *p)
{
	for (uint8_t i = 0; i < LINKS; i++) {
		const uint8_t *base = (const uint8_t *)&links[i];

		if ((const uint8_t *)p >= base && (const uint8_t *)p < base + sizeof(links[i])) {
			return &links[i];
		}
	}
	return NULL;
}

static uint8_t link_of_conn(const struct bt_conn *c)
{
	for (uint8_t i = 0; i < LINKS; i++) {
		if (c != NULL && links[i].conn == c) {
			return i;
		}
	}
	return SCHED_NO_LINK;
}

/* ---- Advertisements (5.1), only while the core listens ---- */

static void scan_recv(const struct bt_le_scan_recv_info *info, struct net_buf_simple *buf)
{
	const uint8_t *p = buf->data;
	size_t left = buf->len;

	if (!atomic_get(&listening) || info->adv_type != BT_GAP_ADV_TYPE_ADV_IND) {
		return; /* mesh traffic is non-connectable */
	}
	while (left >= 2u) {
		size_t len = p[0];

		if (len == 0u || len + 1u > left) {
			return;
		}
		/* [11][0xFF][company u16][ver][tag_id u32][flags][disp_rev u16] */
		if (p[1] == BT_DATA_MANUFACTURER_DATA && len == 1u + ADV_MSD_LEN &&
		    sys_get_le16(&p[2]) == CTAG_MESH_COMPANY_ID &&
		    (p[4] == 1u || p[4] == CTAG_SECURE_PROTO_VERSION)) {
			struct gw_evt e = {
				.type = GW_EVT_TAG_ADV,
				.op = p[4],
				.rssi = info->rssi,
				.u16 = p[9],
				.tag = sys_get_le32(&p[5]),
				.len = 7u,
			};

			e.data[0] = info->addr->type;
			memcpy(&e.data[1], info->addr->a.val, sizeof(info->addr->a.val));
			if (!gw_post_advert(&e)) {
				atomic_inc(&adv_dropped);
			}
			return;
		}
		p += len + 1u;
		left -= len + 1u;
	}
}

static struct bt_le_scan_cb scan_cb = {.recv = scan_recv};

/* ---- Connections (5.2) ---- */

static bool ours(struct bt_conn *c)
{
	struct bt_conn_info info;

	return bt_conn_get_info(c, &info) == 0 && info.role == BT_CONN_ROLE_CENTRAL;
}

static void post_conn(uint8_t type, struct bt_conn *c, uint8_t err)
{
	struct gw_evt e = {.type = type, .err = err};

	memcpy(e.data, &c, sizeof(c));
	gw_post(&e);
}

static void connected(struct bt_conn *c, uint8_t err)
{
	if (ours(c)) {
		post_conn(GW_EVT_CONN, c, err);
	}
}

static void disconnected(struct bt_conn *c, uint8_t reason)
{
	if (ours(c)) {
		post_conn(GW_EVT_DISCONN, c, reason);
	}
}

BT_CONN_CB_DEFINE(gw_conn_cbs) = {
	.connected = connected,
	.disconnected = disconnected,
};

/* ---- GATT setup ---- */

static void post_step(const struct clink *cl, uint16_t step, int err)
{
	struct gw_evt e = {.type = GW_EVT_GATT, .addr = index_of(cl), .u16 = step, .err = err};

	gw_post(&e);
}

static uint8_t disc_cb(struct bt_conn *c, const struct bt_gatt_attr *attr,
		       struct bt_gatt_discover_params *params)
{
	struct clink *cl = CONTAINER_OF(params, struct clink, disc);
	struct handles *h = &cl->h;

	ARG_UNUSED(c);
	if (attr == NULL) {
		post_step(cl, STEP_DISCOVERED, 0); /* this discovery phase is complete */
		return BT_GATT_ITER_STOP;
	}
	switch (params->type) {
	case BT_GATT_DISCOVER_PRIMARY: {
		const struct bt_gatt_service_val *svc = attr->user_data;

		h->start = attr->handle;
		h->end = svc->end_handle;
		post_step(cl, STEP_DISCOVERED, 0);
		return BT_GATT_ITER_STOP;
	}
	case BT_GATT_DISCOVER_CHARACTERISTIC: {
		const struct bt_gatt_chrc *chrc = attr->user_data;

		if (bt_uuid_cmp(chrc->uuid, &caps_uuid.uuid) == 0) {
			h->caps = chrc->value_handle;
		} else if (bt_uuid_cmp(chrc->uuid, &ctrl_uuid.uuid) == 0) {
			h->ctrl = chrc->value_handle;
		} else if (bt_uuid_cmp(chrc->uuid, &data_uuid.uuid) == 0) {
			h->data = chrc->value_handle;
		} else if (bt_uuid_cmp(chrc->uuid, &status_uuid.uuid) == 0) {
			h->status = chrc->value_handle;
		} else if (bt_uuid_cmp(chrc->uuid, &ident_uuid.uuid) == 0) {
			h->ident = chrc->value_handle;
		} else if (bt_uuid_cmp(chrc->uuid, &pair_uuid.uuid) == 0) {
			h->pair = chrc->value_handle;
		}
		return BT_GATT_ITER_CONTINUE;
	}
	default: {
		/* A CCC belongs to the closest characteristic value before it. */
		const uint16_t values[] = {h->caps, h->ctrl, h->data, h->status, h->ident, h->pair};
		uint16_t owner = 0u;

		for (size_t i = 0; i < ARRAY_SIZE(values); i++) {
			if (values[i] < attr->handle && values[i] > owner) {
				owner = values[i];
			}
		}
		if (owner != 0u && owner == h->ctrl) {
			h->ctrl_ccc = attr->handle;
		} else if (owner != 0u && owner == h->status) {
			h->status_ccc = attr->handle;
		} else if (owner != 0u && owner == h->pair) {
			h->pair_ccc = attr->handle;
		}
		return BT_GATT_ITER_CONTINUE;
	}
	}
}

static int discover(struct clink *cl, uint8_t type, const struct bt_uuid *uuid, uint16_t start,
		    uint16_t end)
{
	memset(&cl->disc, 0, sizeof(cl->disc));
	cl->disc.uuid = uuid;
	cl->disc.func = disc_cb;
	cl->disc.start_handle = start;
	cl->disc.end_handle = end;
	cl->disc.type = type;
	return bt_gatt_discover(cl->conn, &cl->disc);
}

static uint8_t value_cb(struct bt_conn *c, struct bt_gatt_subscribe_params *params,
			const void *data, uint16_t len)
{
	struct clink *cl = owner_of(params);
	struct gw_evt e = {.type = GW_EVT_LINK_VALUE};

	ARG_UNUSED(c);
	if (data == NULL || cl == NULL) {
		return BT_GATT_ITER_STOP; /* unsubscribed (the link went down) */
	}
	e.addr = index_of(cl);
	e.op = cl->sub_chr[params == &cl->sub[0] ? 0 : 1];
	if (len > sizeof(e.data)) {
		e.err = -EMSGSIZE; /* the core ends the tunnel (5.3: an overlong fragment) */
	} else {
		e.len = (uint8_t)len;
		memcpy(e.data, data, len);
	}
	gw_post(&e);
	return BT_GATT_ITER_CONTINUE;
}

static void subscribe_cb(struct bt_conn *c, uint8_t err, struct bt_gatt_subscribe_params *params)
{
	struct clink *cl = owner_of(params);

	ARG_UNUSED(c);
	if (cl != NULL) {
		post_step(cl, STEP_SUBSCRIBED, err);
	}
}

static int subscribe(struct clink *cl, uint8_t k, uint8_t chr, uint16_t value, uint16_t ccc,
		     uint16_t v)
{
	struct bt_gatt_subscribe_params *p = &cl->sub[k];

	memset(p, 0, sizeof(*p));
	cl->sub_chr[k] = chr;
	p->notify = value_cb;
	p->subscribe = subscribe_cb;
	p->value_handle = value;
	p->ccc_handle = ccc;
	p->value = v;
	return bt_gatt_subscribe(cl->conn, p);
}

static uint8_t read_cb(struct bt_conn *c, uint8_t err, struct bt_gatt_read_params *params,
		       const void *data, uint16_t len)
{
	struct clink *cl = CONTAINER_OF(params, struct clink, rd);
	struct gw_evt e = {.type = GW_EVT_GATT, .addr = index_of(cl), .u16 = STEP_READ, .err = err};

	ARG_UNUSED(c);
	if (err == 0u && data != NULL) {
		if (len <= sizeof(cl->read_buf) - cl->read_len) {
			memcpy(&cl->read_buf[cl->read_len], data, len);
			cl->read_len += len;
			return BT_GATT_ITER_CONTINUE; /* a long read goes on with Read Blob */
		}
		e.err = -EMSGSIZE; /* never relayed cut: the companion binds the exact value */
	} else if (err == 0u) {
		e.len = (uint8_t)cl->read_len; /* complete */
		memcpy(e.data, cl->read_buf, cl->read_len);
	}
	gw_post(&e);
	return BT_GATT_ITER_STOP;
}

static int read_value(struct clink *cl, uint16_t handle)
{
	cl->read_len = 0u;
	memset(&cl->rd, 0, sizeof(cl->rd));
	cl->rd.func = read_cb;
	cl->rd.handle_count = 1;
	cl->rd.single.handle = handle;
	cl->rd.single.offset = 0;
	return bt_gatt_read(cl->conn, &cl->rd);
}

/* The setup ended: the core opens the tunnel or closes it with status. */
static void setup_done(struct gw_core *g, uint8_t i, uint8_t status, const uint8_t *value,
		       size_t len, int64_t now)
{
	links[i].phase = status == CTAG_STATUS_OK ? PH_READY : PH_IDLE;
	if (status != CTAG_STATUS_OK) {
		gatt_failures++;
		LOG_INF("link %u: GATT setup failed (%u)", i, status);
	}
	gw_core_link_ready(g, i, status, value, len, now);
}

static void gatt_step(struct gw_core *g, uint8_t i, const struct gw_evt *e, int64_t now)
{
	struct clink *cl = &links[i];
	const struct handles *h = &cl->h;
	bool session = cl->mode == CTAG_TUNNEL_MODE_SESSION;
	int err;

	if (cl->conn == NULL) {
		return; /* the link went down meanwhile */
	}
	switch (cl->phase) {
	case PH_PRIMARY:
		if (e->u16 != STEP_DISCOVERED) {
			break;
		}
		if (h->start == 0u) {
			setup_done(g, i, CTAG_STATUS_UNSUPPORTED, NULL, 0u, now); /* no tag service */
		} else if (discover(cl, BT_GATT_DISCOVER_CHARACTERISTIC, NULL, h->start + 1u,
				    h->end) != 0) {
			setup_done(g, i, CTAG_STATUS_INVALID, NULL, 0u, now);
		} else {
			cl->phase = PH_CHRC;
		}
		break;
	case PH_CHRC:
		if (e->u16 != STEP_DISCOVERED) {
			break;
		}
		if (session ? (h->caps == 0u || h->ctrl == 0u || h->data == 0u || h->status == 0u)
			    : (h->ident == 0u || h->pair == 0u)) {
			setup_done(g, i, CTAG_STATUS_UNSUPPORTED, NULL, 0u, now); /* 11.3 */
		} else if (discover(cl, BT_GATT_DISCOVER_DESCRIPTOR, &ccc_uuid.uuid, h->start + 1u,
				    h->end) != 0) {
			setup_done(g, i, CTAG_STATUS_INVALID, NULL, 0u, now);
		} else {
			cl->phase = PH_CCC;
		}
		break;
	case PH_CCC:
		if (e->u16 != STEP_DISCOVERED) {
			break;
		}
		if (session ? (h->ctrl_ccc == 0u || h->status_ccc == 0u) : h->pair_ccc == 0u) {
			setup_done(g, i, CTAG_STATUS_UNSUPPORTED, NULL, 0u, now);
			break;
		}
		cl->phase = PH_SUBSCRIBE;
		cl->subscribed = 0u;
		if (session) {
			cl->subs = 2u;
			err = subscribe(cl, 0u, GW_CHR_CTRL, h->ctrl, h->ctrl_ccc, BT_GATT_CCC_INDICATE);
			if (err == 0) {
				err = subscribe(cl, 1u, GW_CHR_STATUS, h->status, h->status_ccc,
						BT_GATT_CCC_NOTIFY);
			}
		} else {
			cl->subs = 1u;
			err = subscribe(cl, 0u, GW_CHR_PAIR, h->pair, h->pair_ccc, BT_GATT_CCC_INDICATE);
		}
		if (err != 0) {
			setup_done(g, i, CTAG_STATUS_INVALID, NULL, 0u, now);
		}
		break;
	case PH_SUBSCRIBE:
		if (e->u16 != STEP_SUBSCRIBED) {
			break;
		}
		if (e->err != 0) {
			setup_done(g, i, CTAG_STATUS_INVALID, NULL, 0u, now);
			break;
		}
		if (++cl->subscribed < cl->subs) {
			break;
		}
		cl->phase = PH_READ;
		if (read_value(cl, session ? h->caps : h->ident) != 0) {
			setup_done(g, i, CTAG_STATUS_INVALID, NULL, 0u, now);
		}
		break;
	case PH_READ:
		if (e->u16 != STEP_READ) {
			break;
		}
		if (e->err != 0) {
			setup_done(g, i, CTAG_STATUS_INVALID, NULL, 0u, now);
		} else {
			setup_done(g, i, CTAG_STATUS_OK, e->data, e->len, now);
		}
		break;
	default:
		break; /* a late step of a setup that already ended */
	}
}

void gw_central_event(struct gw_core *g, const struct gw_evt *e, int64_t now)
{
	struct bt_conn *c;
	uint8_t i;

	if (e->type == GW_EVT_GATT) {
		if (e->addr < LINKS) {
			gatt_step(g, (uint8_t)e->addr, e, now);
		}
		return;
	}
	memcpy(&c, e->data, sizeof(c));
	i = link_of_conn(c);
	if (i == SCHED_NO_LINK) {
		return; /* not a connection of ours (any more) */
	}
	if (e->type == GW_EVT_CONN) {
		if (e->err != 0) {
			bt_conn_unref(links[i].conn); /* the attempt failed or was cancelled */
			links[i].conn = NULL;
		}
		gw_core_link_connected(g, i, (uint8_t)e->err, now);
		return;
	}
	bt_conn_unref(links[i].conn);
	links[i].conn = NULL;
	links[i].phase = PH_IDLE;
	gw_core_link_disconnected(g, i, (uint8_t)e->err, now);
}

/* ---- Backend (struct gw_backend) ---- */

void gw_central_listen(void *ctx, bool on)
{
	ARG_UNUSED(ctx);
	(void)atomic_set(&listening, on ? 1 : 0);
}

int gw_central_suspend(void *ctx)
{
	ARG_UNUSED(ctx);
	return bt_mesh_suspend();
}

int gw_central_resume(void *ctx)
{
	ARG_UNUSED(ctx);
	return bt_mesh_resume();
}

int gw_central_connect(void *ctx, uint8_t link, const struct sched_peer *peer, uint32_t timeout_ms)
{
	struct bt_conn_le_create_param cp = BT_CONN_LE_CREATE_PARAM_INIT(
		BT_CONN_LE_OPT_NONE, BT_GAP_SCAN_FAST_WINDOW, BT_GAP_SCAN_FAST_WINDOW);
	struct bt_le_conn_param lp = BT_LE_CONN_PARAM_INIT(CONN_INT_MIN, CONN_INT_MAX, 0,
							   CONN_TIMEOUT);
	bt_addr_le_t addr = {.type = peer->type};
	struct clink *cl;

	ARG_UNUSED(ctx);
	if (link >= LINKS) {
		return -EINVAL;
	}
	cl = &links[link];
	memcpy(addr.a.val, peer->a, sizeof(addr.a.val));
	cp.timeout = (uint16_t)(timeout_ms / 10u); /* 10 ms units */
	if (cl->conn != NULL) {
		bt_conn_unref(cl->conn);
		cl->conn = NULL;
	}
	cl->phase = PH_IDLE;
	return bt_conn_le_create(&addr, &cp, &lp, &cl->conn);
}

int gw_central_disconnect(void *ctx, uint8_t link)
{
	ARG_UNUSED(ctx);
	if (link >= LINKS || links[link].conn == NULL) {
		return -ENOTCONN;
	}
	/* On an attempt still initiating this is the cancellation (connected()
	 * then reports it with an error). */
	return bt_conn_disconnect(links[link].conn, BT_HCI_ERR_REMOTE_USER_TERM_CONN);
}

int gw_central_setup(void *ctx, uint8_t link, uint8_t mode)
{
	struct clink *cl;

	ARG_UNUSED(ctx);
	if (link >= LINKS || links[link].conn == NULL) {
		return -ENOTCONN;
	}
	cl = &links[link];
	memset(&cl->h, 0, sizeof(cl->h));
	cl->mode = mode;
	cl->phase = PH_PRIMARY;
	return discover(cl, BT_GATT_DISCOVER_PRIMARY, &svc_uuid.uuid, BT_ATT_FIRST_ATTRIBUTE_HANDLE,
			BT_ATT_LAST_ATTRIBUTE_HANDLE);
}

static void write_cb(struct bt_conn *c, uint8_t err, struct bt_gatt_write_params *params)
{
	struct clink *cl = CONTAINER_OF(params, struct clink, wr);
	struct gw_evt e = {
		.type = GW_EVT_LINK_WRITTEN, .addr = index_of(cl), .op = cl->wr_chr, .err = err};

	ARG_UNUSED(c);
	gw_post(&e);
}

static void data_sent_cb(struct bt_conn *c, void *user_data)
{
	struct gw_evt e = {
		.type = GW_EVT_LINK_WRITTEN, .addr = (uint16_t)(uintptr_t)user_data, .op = GW_CHR_DATA};

	ARG_UNUSED(c);
	gw_post(&e);
}

int gw_central_write(void *ctx, uint8_t link, uint8_t chr, const uint8_t *value, size_t len)
{
	struct clink *cl;

	ARG_UNUSED(ctx);
	if (link >= LINKS || links[link].conn == NULL || links[link].phase != PH_READY) {
		return -ENOTCONN;
	}
	cl = &links[link];
	if (len > sizeof(cl->wr_buf)) {
		return -EMSGSIZE;
	}
	if (chr == GW_CHR_DATA) {
		/* Copied into an ATT buffer at once; its sent callback completes it. */
		return bt_gatt_write_without_response_cb(cl->conn, cl->h.data, value, (uint16_t)len,
							 false, data_sent_cb,
							 (void *)(uintptr_t)link);
	}
	if (chr != GW_CHR_CTRL && chr != GW_CHR_PAIR) {
		return -EINVAL;
	}
	/* With response, one at a time per link (the core's rule): the buffer
	 * stays valid until write_cb. */
	memcpy(cl->wr_buf, value, len);
	memset(&cl->wr, 0, sizeof(cl->wr));
	cl->wr_chr = chr;
	cl->wr.func = write_cb;
	cl->wr.handle = chr == GW_CHR_CTRL ? cl->h.ctrl : cl->h.pair;
	cl->wr.offset = 0;
	cl->wr.data = cl->wr_buf;
	cl->wr.length = (uint16_t)len;
	return bt_gatt_write(cl->conn, &cl->wr);
}

void gw_central_init(void)
{
	bt_le_scan_cb_register(&scan_cb);
}

size_t gw_central_counters(struct ctag_cbor_counter *items, size_t max)
{
	const struct ctag_cbor_counter all[] = {
		CTAG_CBOR_COUNTER("radio_adv_dropped", (uint32_t)atomic_get(&adv_dropped)),
		CTAG_CBOR_COUNTER("gatt_failures", gatt_failures),
	};
	size_t n = ARRAY_SIZE(all) < max ? ARRAY_SIZE(all) : max;

	memcpy(items, all, n * sizeof(all[0]));
	return n;
}
```

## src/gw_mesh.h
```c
/* Firmware backend of the gateway core: mesh (mesh.c), settings (store.c) and
 * the own radio's tag links (central.c). */
#ifndef GW_MESH_H_
#define GW_MESH_H_

#include <stddef.h>
#include <stdint.h>

#include "gw_core.h"

/* mesh.c */
int gw_mesh_start(void); /* bt_enable, mesh, settings, CDB, self-provisioning */
void gw_mesh_load_nodes(struct gw_core *g);
int gw_mesh_send(void *ctx, uint16_t dst, uint8_t op, const uint8_t *params, size_t len,
		 uint32_t tag);
int gw_mesh_cfg(void *ctx, uint16_t addr, uint8_t step, uint8_t arg, uint32_t tag);
int gw_mesh_provision(void *ctx, const uint8_t uuid[16], const uint8_t *static_oob);
void gw_mesh_node_configured(void *ctx, uint16_t addr);
void gw_mesh_node_delete(void *ctx, uint16_t addr);
int gw_sha256(void *ctx, const uint8_t *data, size_t len, uint8_t out[32]);
size_t gw_mesh_counters(struct ctag_cbor_counter *items, size_t max);
#ifdef CONFIG_CTAG_GW_SECURE
/* Wipe the network: names, assignments, the CDB and the node state (v2). */
void gw_mesh_wipe(void *ctx);
#endif

/* store.c: bridge names and assignments under the settings key "ctag/gw". */
void gw_store_name(void *ctx, uint16_t addr, const char *name, size_t len);
void gw_store_assignments(void *ctx, const struct gw_assign *a, size_t n);
/* Hand what settings_load() found to the core (after its nodes were added). */
void gw_store_apply(struct gw_core *g);
#ifdef CONFIG_CTAG_GW_SECURE
/*
 * v2 records (connect-setup.md 2.1, 4.1): the identity key "ctag/gw/id"
 * (generated at first boot, never exported), the ownership record
 * "ctag/gw/own" and the generation floor "ctag/gw/genf".
 */
bool gw_store_identity(uint8_t ik[32]);
int gw_store_save_identity(const uint8_t ik[32]);
/* The stored record (NULL, 0 = none) and floor, as settings_load() found them. */
void gw_store_owner(const uint8_t **rec, size_t *len, uint32_t *floor);
/* Backend store_owner: raise the floor to gen, then write the record. */
int gw_store_save_owner(void *ctx, const uint8_t rec[CTAG_OWNER_RECORD_LEN], uint32_t gen);
#endif

#ifdef CONFIG_CTAG_GW_RADIO
/* central.c: the own radio's backend functions (docs/protocol.md 11). */
/* After gw_mesh_start() succeeded: the tag advertisement listener. */
void gw_central_init(void);
void gw_central_listen(void *ctx, bool on);
int gw_central_suspend(void *ctx);
int gw_central_resume(void *ctx);
int gw_central_connect(void *ctx, uint8_t link, const struct sched_peer *peer, uint32_t timeout_ms);
int gw_central_disconnect(void *ctx, uint8_t link);
int gw_central_setup(void *ctx, uint8_t link, uint8_t mode);
int gw_central_write(void *ctx, uint8_t link, uint8_t chr, const uint8_t *value, size_t len);
size_t gw_central_counters(struct ctag_cbor_counter *items, size_t max);
#endif

#endif /* GW_MESH_H_ */
```
